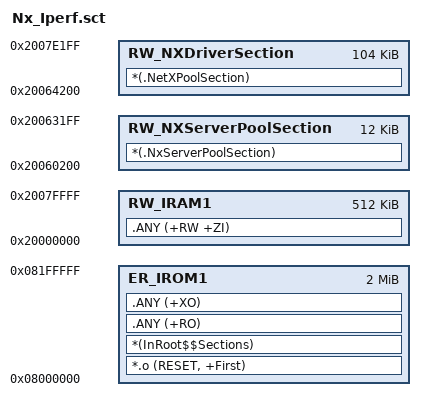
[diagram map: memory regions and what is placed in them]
; *************************************************************
; *** Scatter-Loading Description File generated by uVision ***
; *************************************************************

LR_IROM1 0x08000000 0x00200000  {    ; load region size_region
  ER_IROM1 0x08000000 0x00200000  {  ; load address = execution address
   *.o (RESET, +First)
   *(InRoot$$Sections)
   .ANY (+RO)
   .ANY (+XO)
  }
  RW_IRAM1 0x20000000 0x00080000  {  ; RW data
   .ANY (+RW +ZI)
  }
   RW_NXServerPoolSection 0x20060200 0x3000  {
  *(.NxServerPoolSection)
  }

   RW_NXDriverSection 0x20064200 0x1A000  {
  *(.NetXPoolSection)
  }
}

